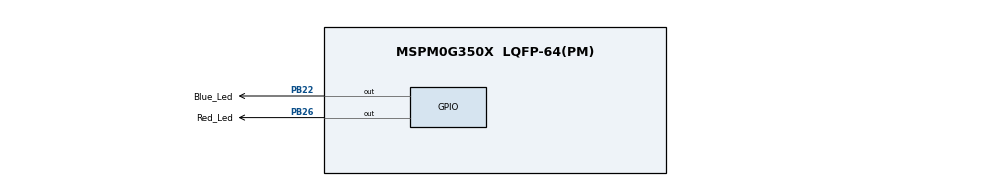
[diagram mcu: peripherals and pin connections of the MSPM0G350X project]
/**
 * @cliArgs --device "MSPM0G350X" --part "Default" --package "LQFP-64(PM)" --product "mspm0_sdk@2.09.00.02"
 * @versions {"tool":"1.25.0+4268"}
 */

/**
 * Import the modules used in this configuration.
 */
const Board         = scripting.addModule("/ti/driverlib/Board");
const GPIO          = scripting.addModule("/ti/driverlib/GPIO", {}, false);
const GPIO1         = GPIO.addInstance();
const SYSCTL        = scripting.addModule("/ti/driverlib/SYSCTL");
const ProjectConfig = scripting.addModule("/ti/project_config/ProjectConfig");

/**
 * Write custom configuration values to the imported modules.
 */

GPIO1.$name                         = "GPIO_LEDS";
GPIO1.portSegment                   = "Upper";
GPIO1.port                          = "PORTB";
GPIO1.associatedPins.create(3);
GPIO1.associatedPins[0].$name       = "Blue_Led";
GPIO1.associatedPins[0].pin.$assign = "PB22";
GPIO1.associatedPins[1].$name       = "Red_Led";
GPIO1.associatedPins[1].pin.$assign = "PB26";
GPIO1.associatedPins[2].$name       = "Green_Led";

SYSCTL.clockTreeEn = true;

/**
 * Pinmux solution for unlocked pins/peripherals. This ensures that minor changes to the automatic solver in a future
 * version of the tool will not impact the pinmux you originally saw.  These lines can be completely deleted in order to
 * re-solve from scratch.
 */
Board.peripheral.$suggestSolution            = "DEBUGSS";
Board.peripheral.swclkPin.$suggestSolution   = "PA20";
Board.peripheral.swdioPin.$suggestSolution   = "PA19";
GPIO1.associatedPins[2].pin.$suggestSolution = "PB16";
